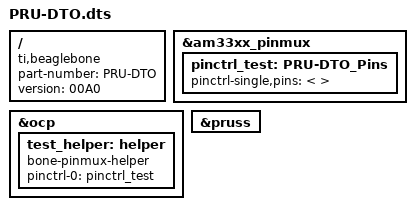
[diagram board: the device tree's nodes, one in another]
/dts-v1/;
/plugin/;

/{
   compatible = "ti,beaglebone", "ti,beaglebone-black";
   part-number = "PRU-DTO";
   version = "00A0";

   fragment@0 {
      target = <&am33xx_pinmux>;
      __overlay__ {
         pinctrl_test: PRU-DTO_Pins {
            pinctrl-single,pins = <
               /* OUTPUT  GPIO(mode7) 0x0f no pullup/pulldown */
               /* INPUT   GPIO(mode7) 0x27 pulldown, 0x37 pullup, 0x2f no pullup/down */


               /********************************************************************************/
               /* All pins in P9 header as outputs, no pullup /*
               /* 0x070 0x0f */   /* P9_11 */
               /* 0x078 0x0f */   /* P9_12 */
               /* 0x074 0x0f */   /* P9_13 */
               /* 0x048 0x0f */   /* P9_14 */
               /* 0x040 0x0f */   /* P9_15 */
               /* 0x04c 0x0f */   /* P9_16 */
               /* 0x15c 0x0f */   /* P9_17 */
               /* 0x158 0x0f */   /* P9_18 */
               /* 0x154 0x0f */   /* P9_21 */
               /* 0x150 0x0f */   /* P9_22 */
               /* 0x044 0x0f */   /* P9_23 */
               /* 0x184 0x0f */   /* P9_24 */
               /* 0x180 0x0f */   /* P9_26 */
               /* 0x1a4 0x0f */   /* P9_27 */
               /* 0x198 0x0f */   /* P9_30 */
               /* 0x1b4 0x0f */   /* P9_41 */
               /* 0x164 0x0f */   /* P9_42 */
               /* 0x054 0x0f */ /* User LED 0 (GPIO1[21])*/
               /* 0x058 0x0f */ /* User LED 1 (GPIO1[22])*/
               /* 0x05c 0x0f */ /* User LED 2 (GPIO1[23])*/
               /* 0x060 0x0f */ /* User LED 3 (GPIO1[24])*/




               /********************************************************************************/
               /* All pins in P9 header as inputs, pulldown /*
               0x070 0x37   /* P9_11  */
               /* 0x078 0x27 */   /* P9_12 */
               /* 0x074 0x27 */   /* P9_13 */
               /* 0x048 0x27 */   /* P9_14 */
               /* 0x040 0x27 */   /* P9_15 */
               /* 0x04c 0x27 */   /* P9_16 */
               /* 0x15c 0x27 */   /* P9_17 */
               /* 0x158 0x27 */   /* P9_18 */
               /* 0x154 0x27 */   /* P9_21 */
               /* 0x150 0x27 */   /* P9_22 */
               /* 0x044 0x27 */   /* P9_23 */
               /* 0x184 0x27 */   /* P9_24 */
               /* 0x180 0x27 */   /* P9_26 */
               /* 0x1a4 0x27 */   /* P9_27 */
               /* 0x198 0x27 */   /* P9_30 */
               /* 0x1b4 0x27 */   /* P9_41 */
               /* 0x164 0x27 */   /* P9_42 */

               /* These 2 as inputs as they share a physical connection with 41 and 42 */
               /* 0x1a8 0x2f */  /* P9_42 */
               /* 0x1a0 0x2f */  /* P9_42 */

            >;
         };
      };
   };

   fragment@1 {
      target = <&ocp>;
      __overlay__ {
         test_helper: helper {
            compatible = "bone-pinmux-helper";
            pinctrl-names = "default";
            pinctrl-0 = <&pinctrl_test>;
            status = "okay";
         };
      };
   };

   fragment@2{
      target = <&pruss>;
      __overlay__ {
         status = "okay";
      };
   };

};
